# STM32L4R7xx register map
File version: 1.0
Registers are 32-bit, access not given, reset 0x0 unless marked. A register's access mark holds for its fields unless they carry their own. Offsets are from the block's base; [hi:lo] are bit positions; {n}, {i} and the like mark numbered series.

## DAC
Base 0x40007400
0x00 CR
  [31] BWST2, [30] CEN2, [30] CAL_FLAG2, [29] DMAUDRIE2, [29] DMAUDR2, [28] DMAEN2, [27:24] MAMP2, [23:22] WAVE2, [31:20] DACC2DHR, [21:18] TSEL2, [17] TEN2, [16] EN2, [27:16] DACC2DHR, [20:16] OTRIM2, [18:16] MODE2, [25:16] THOLD2, [23:16] TREFRESH2, [15] HFSEL, [15] BWST1, [14] CEN1, [14] CAL_FLAG1, [13] DMAUDRIE1, [13] DMAUDR1, [12] DMAEN1, [11:8] MAMP1, [15:8] DACC2DHR, [7:6] WAVE1, [15:4] DACC1DHR, [15:4] DACC2DHR, [15:4] DACC1DHR, [5:2] TSEL1, [1] TEN1, [1] SWTRIG2, [0] EN1, [0] SWTRIG1, [11:0] DACC1DHR, [7:0] DACC1DHR, [11:0] DACC2DHR, [7:0] DACC2DHR, [11:0] DACC1DHR, [7:0] DACC1DHR, [11:0] DACC1DOR, [11:0] DACC2DOR, [4:0] OTRIM1, [2:0] MODE1, [9:0] TSAMPLE1, [9:0] TSAMPLE2, [9:0] THOLD1, [7:0] TREFRESH1
0x04 SWTRIGR
0x08 DHR12R1
0x0C DHR12L1
0x10 DHR8R1
0x14 DHR12R2
0x18 DHR12L2
0x1C DHR8R2
0x20 DHR12RD
0x24 DHR12LD
0x28 DHR8RD
0x2C DOR1
0x30 DOR2
0x34 SR
0x38 CCR
0x3C MCR
0x40 SHSR1
0x44 SHSR2
0x48 SHHR
0x4C SHRR

## DAC1
Base 0x40007400
0x00 CR
  [31] BWST2, [30] CEN2, [30] CAL_FLAG2, [29] DMAUDRIE2, [29] DMAUDR2, [28] DMAEN2, [27:24] MAMP2, [23:22] WAVE2, [31:20] DACC2DHR, [21:18] TSEL2, [17] TEN2, [16] EN2, [27:16] DACC2DHR, [20:16] OTRIM2, [18:16] MODE2, [25:16] THOLD2, [23:16] TREFRESH2, [15] HFSEL, [15] BWST1, [14] CEN1, [14] CAL_FLAG1, [13] DMAUDRIE1, [13] DMAUDR1, [12] DMAEN1, [11:8] MAMP1, [15:8] DACC2DHR, [7:6] WAVE1, [15:4] DACC1DHR, [15:4] DACC2DHR, [15:4] DACC1DHR, [5:2] TSEL1, [1] TEN1, [1] SWTRIG2, [0] EN1, [0] SWTRIG1, [11:0] DACC1DHR, [7:0] DACC1DHR, [11:0] DACC2DHR, [7:0] DACC2DHR, [11:0] DACC1DHR, [7:0] DACC1DHR, [11:0] DACC1DOR, [11:0] DACC2DOR, [4:0] OTRIM1, [2:0] MODE1, [9:0] TSAMPLE1, [9:0] TSAMPLE2, [9:0] THOLD1, [7:0] TREFRESH1
0x04 SWTRIGR
0x08 DHR12R1
0x0C DHR12L1
0x10 DHR8R1
0x14 DHR12R2
0x18 DHR12L2
0x1C DHR8R2
0x20 DHR12RD
0x24 DHR12LD
0x28 DHR8RD
0x2C DOR1
0x30 DOR2
0x34 SR
0x38 CCR
0x3C MCR
0x40 SHSR1
0x44 SHSR2
0x48 SHHR
0x4C SHRR

## OPAMP
Base 0x40007800
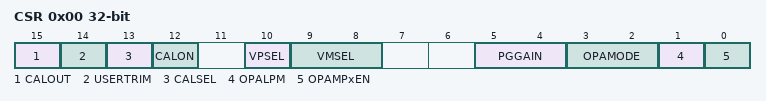
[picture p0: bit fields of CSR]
0x00 CSR
  [15] CALOUT, [14] USERTRIM, [13] CALSEL, [12] CALON, [10] VPSEL, [9:8] VMSEL, [12:8] TRIMOFFSETP, [12:8] TRIMLPOFFSETP, [5:4] PGGAIN, [3:2] OPAMODE, [1] OPALPM, [0] OPAMPxEN, [4:0] TRIMOFFSETN, [4:0] TRIMLPOFFSETN
0x04 OTR
0x08 LPOTR

## OPAMP1
Base 0x40007800
Same registers: OPAMP2 0x40007810
0x00 CSR
  [15] CALOUT, [14] USERTRIM, [13] CALSEL, [12] CALON, [10] VPSEL, [9:8] VMSEL, [12:8] TRIMOFFSETP, [12:8] TRIMLPOFFSETP, [5:4] PGGAIN, [3:2] OPAMODE, [1] OPALPM, [0] OPAMPxEN, [4:0] TRIMOFFSETN, [4:0] TRIMLPOFFSETN
0x04 OTR
0x08 LPOTR

## OPAMP12_COMMON
Base 0x40007800
0x00 CSR
  [15] CALOUT, [14] USERTRIM, [13] CALSEL, [12] CALON, [10] VPSEL, [9:8] VMSEL, [5:4] PGGAIN, [3:2] OPAMODE, [1] OPALPM, [0] OPAMPxEN

## LPTIM1
Base 0x40007C00
Same registers: LPTIM2 0x40009400
0x00 ISR
  [24] ENC, [23] COUNTMODE, [22] PRELOAD, [21] WAVPOL, [20] WAVE, [19] TIMOUT, [18:17] TRIGEN, [15:13] TRIGSEL, [11:9] PRESC, [6] DOWN, [6] DOWNCF, [6] DOWNIE, [7:6] TRGFLT, [5] UP, [5] UPCF, [5] UPIE, [4] ARROK, [4] ARROKCF, [4] ARROKIE, [3] CMPOK, [3] CMPOKCF, [3] CMPOKIE, [4:3] CKFLT, [2] EXTTRIG, [2] EXTTRIGCF, [2] EXTTRIGIE, [2] CNTSTRT, [1] ARRM, [1] ARRMCF, [1] ARRMIE, [2:1] CKPOL, [1] SNGSTRT, [0] CMPM, [0] CMPMCF, [0] CMPMIE, [0] CKSEL, [0] ENABLE, [15:0] CMP, [15:0] ARR, [15:0] CNT, [1:0] OR
0x04 ICR
0x08 IER
0x0C CFGR
0x10 CR
0x14 CMP
0x18 ARR
0x1C CNT
0x20 OR

## SYSCFG
Base 0x40010000
0x00 MEMRMP
  [n] PAGE{n} (n=0..31), [n-32] PAGE{n} (n=32..63), [n+19] I2C{n}_FMP (n=1..4), [n+10] I2C_PB{n}_FMP (n=6..9), [4n+3:4n] EXTI{n} (n=0..3), [4n-13:4n-16] EXTI{n} (n=4..7), [4n-29:4n-32] EXTI{n} (n=8..11), [4n-46:4n-48] EXTI{n} (n=12..15), [8] FB_MODE, [8] BOOSTEN, [8] SPF, [3] ECCL, [2] PVDL, [1] SRAM2BSY, [1] SPL, [2:0] MEM_MODE, [0] FWDIS, [0] SRAM2ER, [0] CLL, [7:0] KEY
0x04 CFGR1
0x08 EXTICR.0
0x0C EXTICR.1
0x10 EXTICR.2
0x14 EXTICR.3
0x18 SCSR
0x1C CFGR2
0x20 SWPR
0x24 SKR
0x28 SWPR2
